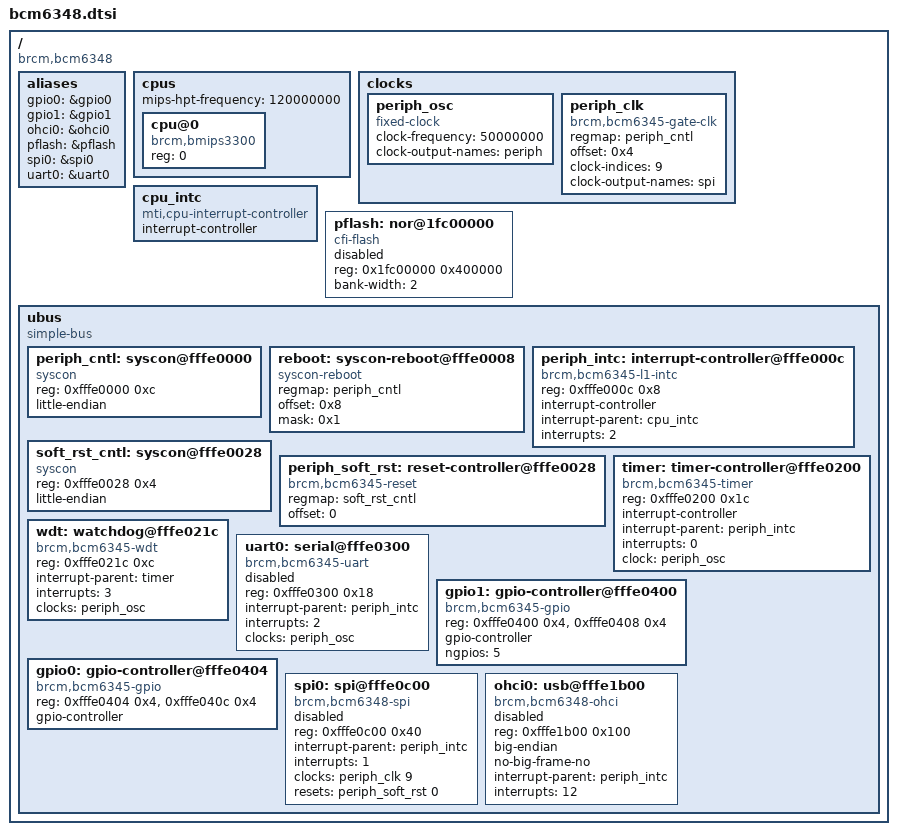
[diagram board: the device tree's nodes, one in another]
#include <dt-bindings/gpio/gpio.h>
#include <dt-bindings/input/input.h>

/ {
	#address-cells = <1>;
	#size-cells = <1>;
	compatible = "brcm,bcm6348";

	aliases {
		gpio0 = &gpio0;
		gpio1 = &gpio1;
		ohci0 = &ohci0;
		pflash = &pflash;
		spi0 = &spi0;
		uart0 = &uart0;
	};

	cpus {
		#address-cells = <1>;
		#size-cells = <0>;
		mips-hpt-frequency = <120000000>;

		cpu@0 {
			compatible = "brcm,bmips3300", "mips,mips4Kc";
			device_type = "cpu";
			reg = <0>;
		};
	};

	clocks {
		periph_osc: periph_osc {
			compatible = "fixed-clock";

			#clock-cells = <0>;

			clock-frequency = <50000000>;
			clock-output-names = "periph";
		};

		periph_clk: periph_clk {
			compatible = "brcm,bcm6345-gate-clk";
			regmap = <&periph_cntl>;
			offset = <0x4>;

			#clock-cells = <1>;

			clock-indices = <9>;
			clock-output-names = "spi";

			/*
			 0: adsl_phy
			 1: mpi
			 2: sdram
			 3: m2m
			 4: enet
			 5: sar
			 6: usbs
			 8: usbh
			 9: spi
			*/
		};
	};

	cpu_intc: cpu_intc {
		#address-cells = <0>;
		compatible = "mti,cpu-interrupt-controller";

		interrupt-controller;
		#interrupt-cells = <1>;
	};

	pflash: nor@1fc00000 {
		#address-cells = <1>;
		#size-cells = <1>;
		compatible = "cfi-flash";
		reg = <0x1fc00000 0x400000>;
		bank-width = <2>;

		status = "disabled";
	};

	ubus {
		#address-cells = <1>;
		#size-cells = <1>;

		compatible = "simple-bus";
		ranges;

		periph_cntl: syscon@fffe0000 {
			compatible = "syscon";
			reg = <0xfffe0000 0xc>;
			little-endian;
		};

		reboot: syscon-reboot@fffe0008 {
			compatible = "syscon-reboot";
			regmap = <&periph_cntl>;
			offset = <0x8>;
			mask = <0x1>;
		};

		periph_intc: interrupt-controller@fffe000c {
			compatible = "brcm,bcm6345-l1-intc";
			reg = <0xfffe000c 0x8>;

			interrupt-controller;
			#interrupt-cells = <1>;

			interrupt-parent = <&cpu_intc>;
			interrupts = <2>;
		};

		soft_rst_cntl: syscon@fffe0028 {
			compatible = "syscon";
			reg = <0xfffe0028 0x4>;
			little-endian;
		};

		periph_soft_rst: reset-controller@fffe0028 {
			compatible = "brcm,bcm6345-reset";
			regmap = <&soft_rst_cntl>;
			offset = <0>;

			#reset-cells = <1>;

			/*
			 0: spi
			 2: emac
			 3: usbh
			 4: usbs
			 5: adsl
			 6: dmamem
			 7: sar
			 8: aclc
			 10: adsl_mips_pll
			*/
		};

		timer: timer-controller@fffe0200 {
			compatible = "brcm,bcm6345-timer";
			reg = <0xfffe0200 0x1c>;

			interrupt-controller;
			#interrupt-cells = <1>;

			interrupt-parent = <&periph_intc>;
			interrupts = <0>;

			clock = <&periph_osc>;
		};

		wdt: watchdog@fffe021c {
			compatible = "brcm,bcm6345-wdt";
			reg = <0xfffe021c 0xc>;

			interrupt-parent = <&timer>;
			interrupts = <3>;

			clocks = <&periph_osc>;
		};

		uart0: serial@fffe0300 {
			compatible = "brcm,bcm6345-uart";
			reg = <0xfffe0300 0x18>;

			interrupt-parent = <&periph_intc>;
			interrupts = <2>;

			clocks = <&periph_osc>;

			status = "disabled";
		};

		gpio1: gpio-controller@fffe0400 {
			compatible = "brcm,bcm6345-gpio";
			reg = <0xfffe0400 0x4>, <0xfffe0408 0x4>;

			gpio-controller;
			#gpio-cells = <2>;

			ngpios = <5>;
		};

		gpio0: gpio-controller@fffe0404 {
			compatible = "brcm,bcm6345-gpio";
			reg = <0xfffe0404 0x4>, <0xfffe040c 0x4>;

			gpio-controller;
			#gpio-cells = <2>;
		};

		spi0: spi@fffe0c00 {
			compatible = "brcm,bcm6348-spi";
			reg = <0xfffe0c00 0x40>;
			#address-cells = <1>;
			#size-cells = <1>;

			interrupt-parent = <&periph_intc>;
			interrupts = <1>;

			clocks = <&periph_clk 9>;
			clock-names = "spi";

			resets = <&periph_soft_rst 0>;

			status = "disabled";
		};

		ohci0: usb@fffe1b00 {
			compatible = "brcm,bcm6348-ohci", "generic-ohci";
			reg = <0xfffe1b00 0x100>;
			big-endian;
			no-big-frame-no;

			interrupt-parent = <&periph_intc>;
			interrupts = <12>;

			status = "disabled";
		};
	};
};
